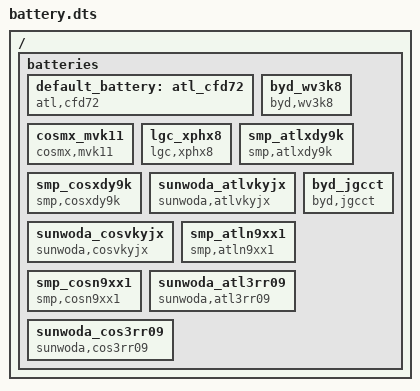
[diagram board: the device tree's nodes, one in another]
/* Copyright 2022 The ChromiumOS Authors
 * Use of this source code is governed by a BSD-style license that can be
 * found in the LICENSE file.
 */

/ {
	batteries {
		default_battery: atl_cfd72 {
			compatible = "atl,cfd72", "battery-smart";
		};
		byd_wv3k8 {
			compatible = "byd,wv3k8", "battery-smart";
		};
		cosmx_mvk11 {
			compatible = "cosmx,mvk11", "battery-smart";
		};
		lgc_xphx8 {
			compatible = "lgc,xphx8", "battery-smart";
		};
		smp_atlxdy9k {
			compatible = "smp,atlxdy9k", "battery-smart";
		};
		smp_cosxdy9k {
			compatible = "smp,cosxdy9k", "battery-smart";
		};
		sunwoda_atlvkyjx {
			compatible = "sunwoda,atlvkyjx", "battery-smart";
		};
		sunwoda_cosvkyjx {
			compatible = "sunwoda,cosvkyjx", "battery-smart";
		};
		smp_atln9xx1 {
			compatible = "smp,atln9xx1", "battery-smart";
		};
		smp_cosn9xx1 {
			compatible = "smp,cosn9xx1", "battery-smart";
		};
		byd_jgcct {
			compatible = "byd,jgcct", "battery-smart";
		};
		sunwoda_atl3rr09 {
			compatible = "sunwoda,atl3rr09", "battery-smart";
		};
		sunwoda_cos3rr09 {
			compatible = "sunwoda,cos3rr09", "battery-smart";
		};
	};
};
